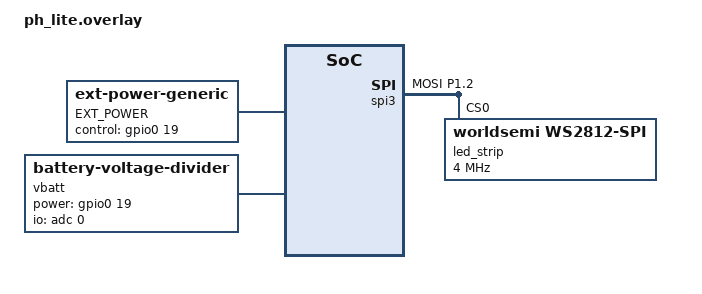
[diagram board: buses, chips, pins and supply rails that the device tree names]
/*
 * Board-specific overlay for PH60-SC_V2 shield on the ph_lite board
 * Following ZMK official underglow guidance: put hardware-specific
 * LED strip and battery divider definitions in a shield/boards/<board>.overlay
 */

#include <dt-bindings/led/led.h>

&pinctrl {
    spi3_default: spi3_default {
        group1 {
            psels = <NRF_PSEL(SPIM_MOSI, 1, 2)>;
        };
    };

    spi3_sleep: spi3_sleep {
        group1 {
            psels = <NRF_PSEL(SPIM_MOSI, 1, 2)>;
            low-power-enable;
        };
    };
};

&spi3 {
    compatible = "nordic,nrf-spim";
    status = "okay";

    pinctrl-0 = <&spi3_default>;
    pinctrl-1 = <&spi3_sleep>;
    pinctrl-names = "default", "sleep";

    led_strip: ws2812@0 {
        compatible = "worldsemi,ws2812-spi";

        /* SPI */
        reg = <0>;
        spi-max-frequency = <4000000>;

        /* WS2812 */
        chain-length = <61>;
        spi-one-frame = <0x70>;
        spi-zero-frame = <0x40>;
        color-mapping = <LED_COLOR_ID_GREEN
                         LED_COLOR_ID_RED
                         LED_COLOR_ID_BLUE>;
    };
};

/ {
    chosen {
        zmk,underglow = &led_strip;
        zmk,led-widgets-dev = &led_strip;
        zmk,leds = &led_strip;
        zmk,battery = &vbatt;
    };

    /* External power control - required for RGB underglow */
    ext_power {
        compatible = "zmk,ext-power-generic";
        label = "EXT_POWER";
        control-gpios = <&gpio0 19 GPIO_ACTIVE_HIGH>;
        init-delay-ms = <50>;
    };

    /* Battery voltage divider (VBATT) on P0.19 */
    vbatt: vbatt {
        compatible = "zmk,battery-voltage-divider";
        io-channels = <&adc 0>;
        power-gpios = <&gpio0 19 GPIO_ACTIVE_HIGH>;
        output-ohms = <2000000>;
        full-ohms = <(2000000 + 806000)>;
    };
};
